# USB_USB_DWC3_53910000h register map
Vendor: Texas Instruments
Registers are 32-bit, read-write, reset 0x0 unless marked. A register's access mark holds for its fields unless they carry their own. Offsets are as the file gives them; [hi:lo] are bit positions; {n}, {i} and the like mark numbered series; 'fields as' and 'values as' point back to an identical list; <NAME> marks a mode.

## USB_DWC3 (part 2 of 2)
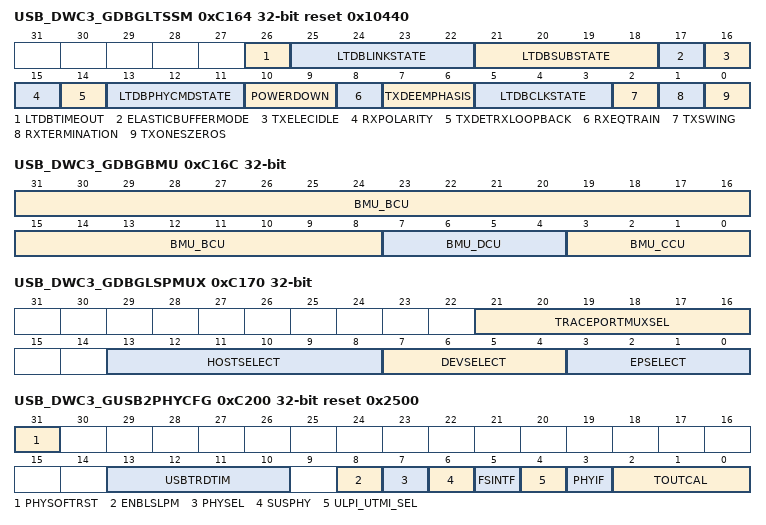
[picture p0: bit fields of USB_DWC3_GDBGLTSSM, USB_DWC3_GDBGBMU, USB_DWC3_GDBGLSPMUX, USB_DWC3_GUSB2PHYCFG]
0xC164 USB_DWC3_GDBGLTSSM ro reset 0x10440 — Global Debug LTSSM (Link Training Super-speed State Machine) Port number is defined by GDBGFIFOSPACE.PortSelect[3:0].
  [26] LTDBTIMEOUT — LTSSM Debug Timeout
  [25:22] LTDBLINKSTATE — LTSSM Debug: Link State
  [21:18] LTDBSUBSTATE — LTSSM Debug: Link Sub-State. Note that the actual reset value [0x0] changes before the register can be read out.
  [17] ELASTICBUFFERMODE — Debug PIPE Status: ElasticBufferMode
  [16] TXELECIDLE — Debug PIPE Status: TxElecIdle
  [15] RXPOLARITY — Debug PIPE Status: RxPolarity
  [14] TXDETRXLOOPBACK — Debug PIPE Status: TxDetRxLoopback
  [13:11] LTDBPHYCMDSTATE — LTSSM Debug Phy Command State.
  [10:9] POWERDOWN — Debug PIPE Status: PowerDown
  [8] RXEQTRAIN — Debug PIPE Status: RxEqTrain
  [7:6] TXDEEMPHASIS — Debug PIPE Status: TxDeemphasis
  [5:3] LTDBCLKSTATE — LTSSM Debug Clock State
  [2] TXSWING — Debug PIPE Status: TxSwing
  [1] RXTERMINATION — Debug PIPE Status: RxTermination
  [0] TXONESZEROS — Debug PIPE Status: TxOnesZeros
0xC168 USB_DWC3_GDBGLNMCC ro — Global Debug LNMCC (Link layer /MAC layer Control).
  [8:0] LNMCC_BERC — LNMCC Bit Error Rate Count: BER information for port selected in GDBGFIFOSPACE.PortSelect
0xC16C USB_DWC3_GDBGBMU ro — Global Debug BMU (Buffer Management Unit).
  [31:8] BMU_BCU — BMU Bus Control Unit: Debug information
  [7:4] BMU_DCU — BMU Datapath Control Unit: Debug information
  [3:0] BMU_CCU — BMU Control-path Control Unit: Debug information
0xC170 USB_DWC3_GDBGLSPMUX — Global Debug LSP MUX, for internal use only.
  [21:16] TRACEPORTMUXSEL — Select the 64-bit analyzer trace vector. Not sensitive to warm reset [ie including software reset], only to power-on reset.
  [13:8] HOSTSELECT — Host LSP Select[13:8]. Valid only in Host mode.
  [7:4] DEVSELECT — Host LSP Select[7:4] in Host mode. Device LSP Select in Device mode
  [3:0] EPSELECT — Host LSP Select[3:0] in Host mode. Device LSP Select in Device mode
0xC174 USB_DWC3_GDBGLSP ro — Global Debug LSP, for internal use only.
  [31:0] DEBUG — LSP debug information
0xC178 USB_DWC3_GDBGEPINFO0 ro — Global Debug Endpoint Information Register 0
  [31:0] DEBUG — EP debug information
0xC17C USB_DWC3_GDBGEPINFO1 ro — Global Debug Endpoint Information Register 1
  [31:0] DEBUG — EP debug information
0xC180 USB_DWC3_GPRTBIMAP_HSLO — Global Port to USB Instance Mapping Register, High-Speed, low bits [31:0].
  [3:0] BINUM1 — HS USB Instance Number for Port number 1. Application-programmable ID field.
0xC184 USB_DWC3_GPRTBIMAP_HSHI access not given reset not defined — Global Port to USB Instance Mapping Register, High-Speed, high bits [63:32].
0xC188 USB_DWC3_GPRTBIMAP_FSLO — Global Port to USB Instance Mapping Register, Full/low-Speed, low bits [31:0].
  [3:0] BINUM1 — FS USB Instance Number for Port number 1. Application-programmable ID field.
0xC18C USB_DWC3_GPRTBIMAP_FSHI access not given reset not defined — Global Port to USB Instance Mapping Register, Full/low-Speed, high bits [63:32].
0xC200 USB_DWC3_GUSB2PHYCFG access per field reset 0x2500 — Global USB2 (UTMI/ULPI) PHY configuration.
  [31] PHYSOFTRST rw — PHY Soft Reset. Active-high, fully static software reset for UTMI USB2 transceiver.
  [13:10] USBTRDTIM rw — USB 2.0 Turnaround Time, in PHY clock cycles. Specifies the response time for a MAC request to the Packet FIFO Controller [PFC] to fetch data from the DFIFO [SPRAM].
  [8] ENBLSLPM rw — Enable UTMI Sleep. Controls assertion of utmi_sleep_n, utmi_l1_suspend_n outputs to the PHY when in the L1 state.
  [7] PHYSEL ro — PHY Select. [HS vs. serial]: Unused, since serial PHY is not supported.
  [6] SUSPHY rw — Suspend enable for USB2.0 HS/FS/LS PHY [ULPI or UTMI]. Set to 1 only after core initialization is complete.
  [5] FSINTF ro — Full-Speed Serial Interface Select. UNUSED.
  [4] ULPI_UTMI_SEL ro — ULPI vs. UTMI+ Select
  [3] PHYIF rw — PHY Interface. DO NOT USE. If UTMI+ is selected, configures 8- or 16-bit interface. If ULPI is selected, configures SDR or DDR mode.
  [2:0] TOUTCAL rw — HS/FS Timeout Calibration. The number of PHY clocks, as indicated by the application in this field, is multiplied by a bit-time factor. This factor is added to the high- speed/full-speed interpacket timeout duration in the core to account for additional delays introduced by the PHY. This may be required, since the delay introduced by the PHY in generating the linestate condition may vary among PHYs. The USB standard timeout value for high-speed operation is 736 to 816 [inclusive] bit times. The USB standard timeout value for full-speed operation is 16 to 18 [inclusive] bit times. The application must program this field based on the speed of connection. The number of bit times added per PHY clock are: High-speed operation: 8 bit times per 60-MHz PHY clock cycle Full-speed operation: [depending on clock speed] 0.2 bit times per 60-MHz PHY clock cycle 0.25 bit times per 48-MHz PHY clock cycle
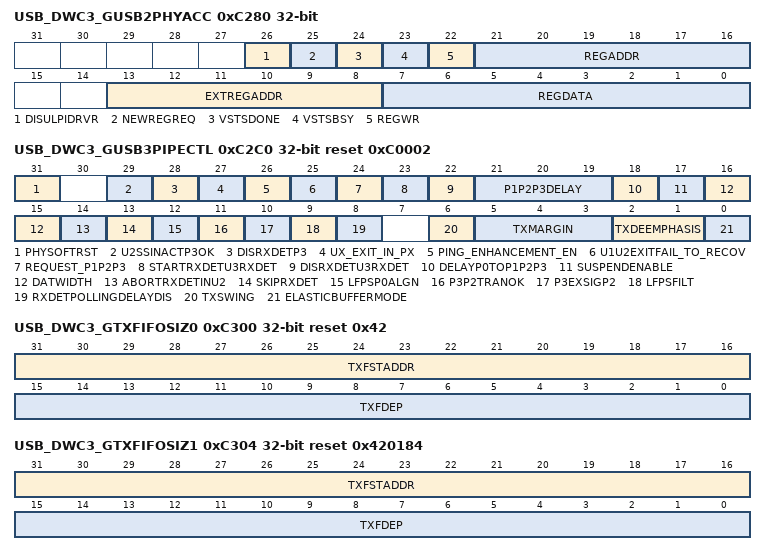
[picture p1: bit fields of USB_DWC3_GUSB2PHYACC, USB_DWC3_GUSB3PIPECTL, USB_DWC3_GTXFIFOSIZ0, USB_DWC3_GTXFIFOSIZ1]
0xC280 USB_DWC3_GUSB2PHYACC access per field — Global USB2 PHY Access.
  [26] DISULPIDRVR ro — Disable ULPI Drivers, for carkit mode. Auto-cleared. NOT USED.
  [25] NEWREGREQ rw — New Register Request. Auto-cleared.
  [24] VSTSDONE ro — VStatus Done
  [23] VSTSBSY ro — VStatus Busy
  [22] REGWR rw — Register Write
  [21:16] REGADDR rw — Register Address. ULPI PHY register address for immediate PHY Register Set access. Set to 6h2F for Extended PHY Register Set access.
  [13:8] EXTREGADDR rw — ULPI: PHY extended register address. UTMI+: unused
  [7:0] REGDATA rw — Register Data [read and write data]
0xC2C0 USB_DWC3_GUSB3PIPECTL access per field reset 0xC0002 — Global USB3 PIPE Control.
  [31] PHYSOFTRST rw — PHY Soft Reset. Active-high, fully static software reset for PIPE USB3 transceiver. Recommendation is to use the core's SW reset instead, or simultaneously.
  [29] U2SSINACTP3OK rw — Use mode P3 for U2/SSInactive states
  [28] DISRXDETP3 rw — Disabled Rx Detection in P3 mode [in the PHY]
  [27] UX_EXIT_IN_PX rw — Workaround for SS PHY injecting a glitch on RxElecIdle while receiving Ux exit LFPS, and PowerDown change is in progress.
  [26] PING_ENHANCEMENT_EN rw — Ping Enhancement Enable: Extended downstream port U1 ping receive timeout. Invalid for Upstream port.
  [25] U1U2EXITFAIL_TO_RECOV rw — Enhancement to prevent interoperability issue in case of incorrect LFPS handshake by the remote link.
  [24] REQUEST_P1P2P3 rw — Control the systematic request of P1/P2/P3 for U1/U2/U3
  [23] STARTRXDETU3RXDET rw — Manual control for periodic Rx detection required in U3 and Rx.Detect, host mode.
  [22] DISRXDETU3RXDET rw — Disable the HW-scheduled periodic Rx detection required in U3 and SS.Disabled, for host mode.
  [21:19] P1P2P3DELAY rw — If DelayP0toP1P2P3=1, delays the transition to P1/P2/P3 when entering U1/U2/U3 until P1P2P3Delay*8b10b errors occur, or RxValid=0 on PIPE.
  [18] DELAYP0TOP1P2P3 rw — Delay PHY change from P0 to P1/P2/P3 when link state changes from U0 to U1/U2/U3, respectively.
  [17] SUSPENDENABLE rw — Suspend Enable for USB3.0 SS PHY. Set to 1 only after core initialization is complete.
  [16:15] DATWIDTH ro — PIPE Data Width [input from phy: refer to PIPE standard]. Field updated to the input's value immediately after reset.
  [14] ABORTRXDETINU2 rw — Abort Rx Detect in U2. For Downstream port only.
  [13] SKIPRXDET rw — Skip Rx Detect. When set, the core skips Rx Detection if pipe signal 'RxElecIdle' is low. Skip is defined as waiting for the appropriate timeout, then repeating the operation.
  [12] LFPSP0ALGN rw — LFPS P0 Align. When set to1: The core deasserts LFPS transmission on the clock edge that it requests Phy power state 0 when exiting U1, U2, or U3 low power states. Otherwise, LFPS transmission is asserted one clock earlier. - The core requests symbol transmission two pipe_rx_pclks periods after The Phy asserts PhyStatus as a result of The Phy switching from Q1 or Q2 state to P0 state.
  [11] P3P2TRANOK rw — P3-to-P2 Transitions OK
  [10] P3EXSIGP2 rw — PHY power state behaviour upon U3 exit handshake.
  [9] LFPSFILT rw — LFPS Filter. When set, filter LFPS reception with pipe 'RxValid' signal in PHY power state P0, that is, ignore LFPS reception from the PHY unless both pipe signals 'RxElecIdle' and 'RxValid' are deasserted.
  [8] RXDETPOLLINGDELAYDIS rw — Disable 400us delay from Rx.Detect to Polling.LFPS
  [6] TXSWING rw — Tx Swing [output to phy: refer to PIPE standard]
  [5:3] TXMARGIN rw — Tx Margin[2:0] [output to phy: refer to PIPE standard]
  [2:1] TXDEEMPHASIS rw — Tx Deemphasis [output to phy: refer to PIPE standard]. The value driven to the PHY is controlled by the LTSSM during USB3 Compliance mode.
  [0] ELASTICBUFFERMODE rw — Elastic Buffer Mode [output to phy: refer to PIPE standard]
0xC300 USB_DWC3_GTXFIFOSIZ0 reset 0x42 — Global Transmit FIFO Size #0: FIFO mapping in RAM1, from staddr to (staddr+dep-1).
  [31:16] TXFSTADDR — Transmit FIFO RAM Start Address, in 64-bit RAM words
  [15:0] TXFDEP — Transmit FIFO Depth, in 64-bit RAM words
0xC304 USB_DWC3_GTXFIFOSIZ1 reset 0x420184 — Global Transmit FIFO Size #1: FIFO mapping in RAM1, from staddr to (staddr+dep-1).
  fields as USB_DWC3_GTXFIFOSIZ0
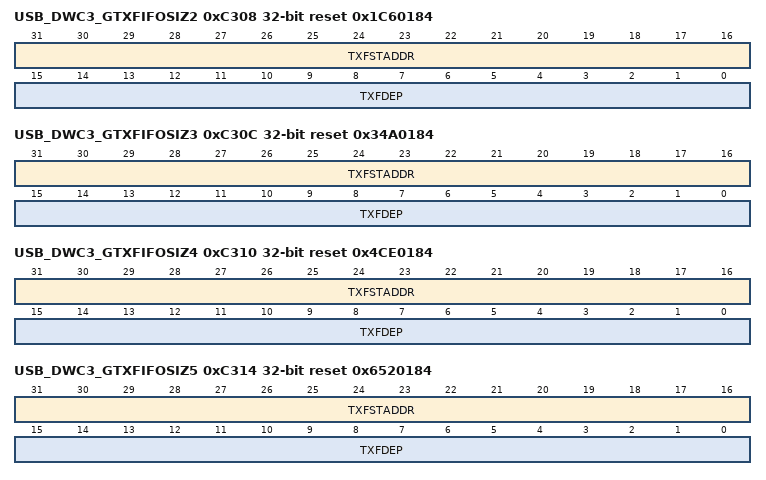
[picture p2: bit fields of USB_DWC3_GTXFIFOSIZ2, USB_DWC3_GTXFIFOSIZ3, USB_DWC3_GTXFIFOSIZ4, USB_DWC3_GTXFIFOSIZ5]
0xC308 USB_DWC3_GTXFIFOSIZ2 reset 0x1C60184 — Global Transmit FIFO Size #2: FIFO mapping in RAM1, from staddr to (staddr+dep-1).
  fields as USB_DWC3_GTXFIFOSIZ0
0xC30C USB_DWC3_GTXFIFOSIZ3 reset 0x34A0184 — Global Transmit FIFO Size #3: FIFO mapping in RAM1, from staddr to (staddr+dep-1).
  fields as USB_DWC3_GTXFIFOSIZ0
0xC310 USB_DWC3_GTXFIFOSIZ4 reset 0x4CE0184 — Global Transmit FIFO Size #4: FIFO mapping in RAM1, from staddr to (staddr+dep-1).
  fields as USB_DWC3_GTXFIFOSIZ0
0xC314 USB_DWC3_GTXFIFOSIZ5 reset 0x6520184 — Global Transmit FIFO Size #5: FIFO mapping in RAM1, from staddr to (staddr+dep-1).
  fields as USB_DWC3_GTXFIFOSIZ0
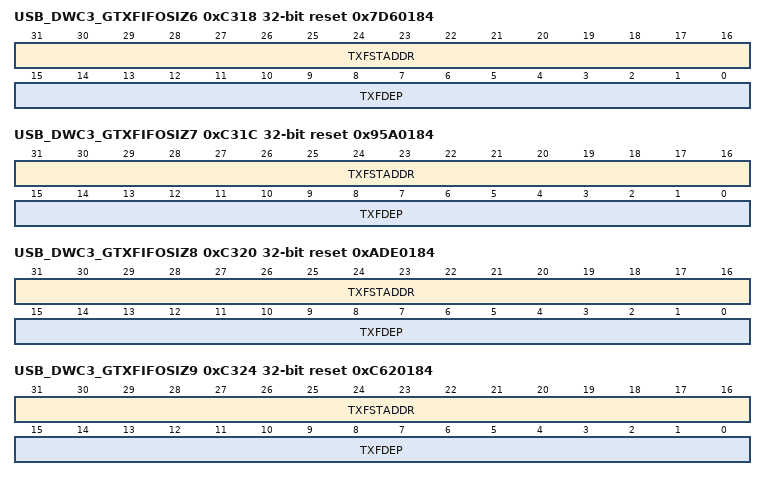
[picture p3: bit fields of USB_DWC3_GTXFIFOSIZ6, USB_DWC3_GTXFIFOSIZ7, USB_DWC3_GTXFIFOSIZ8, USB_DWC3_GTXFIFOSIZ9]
0xC318 USB_DWC3_GTXFIFOSIZ6 reset 0x7D60184 — Global Transmit FIFO Size #6: FIFO mapping in RAM1, from staddr to (staddr+dep-1).
  fields as USB_DWC3_GTXFIFOSIZ0
0xC31C USB_DWC3_GTXFIFOSIZ7 reset 0x95A0184 — Global Transmit FIFO Size #7: FIFO mapping in RAM1, from staddr to (staddr+dep-1).
  fields as USB_DWC3_GTXFIFOSIZ0
0xC320 USB_DWC3_GTXFIFOSIZ8 reset 0xADE0184 — Global Transmit FIFO Size #8: FIFO mapping in RAM1, from staddr to (staddr+dep-1).
  fields as USB_DWC3_GTXFIFOSIZ0
0xC324 USB_DWC3_GTXFIFOSIZ9 reset 0xC620184 — Global Transmit FIFO Size #9: FIFO mapping in RAM1, from staddr to (staddr+dep-1).
  fields as USB_DWC3_GTXFIFOSIZ0
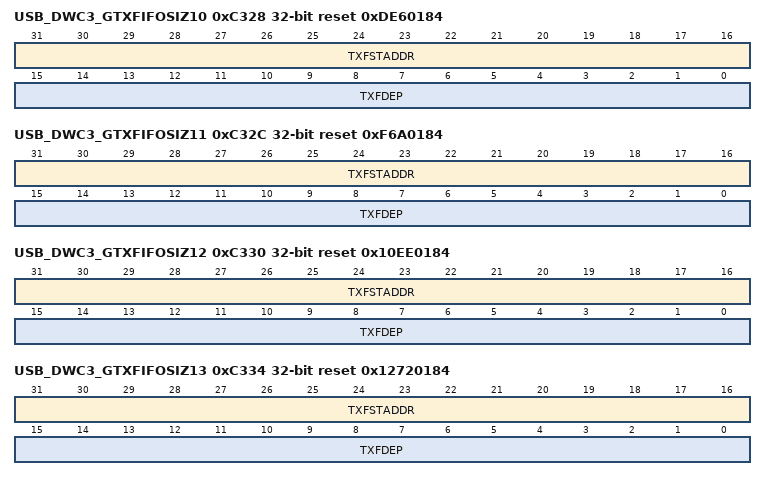
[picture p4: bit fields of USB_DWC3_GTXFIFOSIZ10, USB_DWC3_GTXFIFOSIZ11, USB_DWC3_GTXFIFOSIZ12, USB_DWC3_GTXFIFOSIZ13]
0xC328 USB_DWC3_GTXFIFOSIZ10 reset 0xDE60184 — Global Transmit FIFO Size #10: FIFO mapping in RAM1, from staddr to (staddr+dep-1).
  fields as USB_DWC3_GTXFIFOSIZ0
0xC32C USB_DWC3_GTXFIFOSIZ11 reset 0xF6A0184 — Global Transmit FIFO Size #11: FIFO mapping in RAM1, from staddr to (staddr+dep-1).
  fields as USB_DWC3_GTXFIFOSIZ0
0xC330 USB_DWC3_GTXFIFOSIZ12 reset 0x10EE0184 — Global Transmit FIFO Size #12: FIFO mapping in RAM1, from staddr to (staddr+dep-1).
  fields as USB_DWC3_GTXFIFOSIZ0
0xC334 USB_DWC3_GTXFIFOSIZ13 reset 0x12720184 — Global Transmit FIFO Size #13: FIFO mapping in RAM1, from staddr to (staddr+dep-1).
  fields as USB_DWC3_GTXFIFOSIZ0
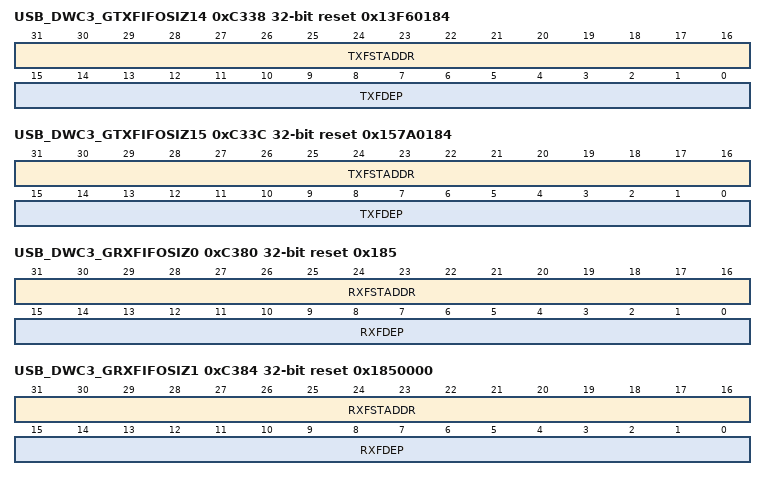
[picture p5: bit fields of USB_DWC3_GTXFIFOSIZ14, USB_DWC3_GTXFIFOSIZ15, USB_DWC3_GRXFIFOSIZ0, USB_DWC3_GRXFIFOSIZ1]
0xC338 USB_DWC3_GTXFIFOSIZ14 reset 0x13F60184 — Global Transmit FIFO Size #14: FIFO mapping in RAM1, from staddr to (staddr+dep-1).
  fields as USB_DWC3_GTXFIFOSIZ0
0xC33C USB_DWC3_GTXFIFOSIZ15 reset 0x157A0184 — Global Transmit FIFO Size #15: FIFO mapping in RAM1, from staddr to (staddr+dep-1).
  fields as USB_DWC3_GTXFIFOSIZ0
0xC380 USB_DWC3_GRXFIFOSIZ0 reset 0x185 — Global Receive FIFO Size #0: FIFO mapping in RAM, from staddr to (staddr+dep-1).
  [31:16] RXFSTADDR — Receive FIFO RAM Start Address, in 64-bit RAM words.
  [15:0] RXFDEP — Receive FIFO Depth, in 64-bit RAM words
0xC384 USB_DWC3_GRXFIFOSIZ1 reset 0x1850000 — Global Receive FIFO Size #1: FIFO mapping in RAM, from staddr to (staddr+dep-1).
  fields as USB_DWC3_GRXFIFOSIZ0
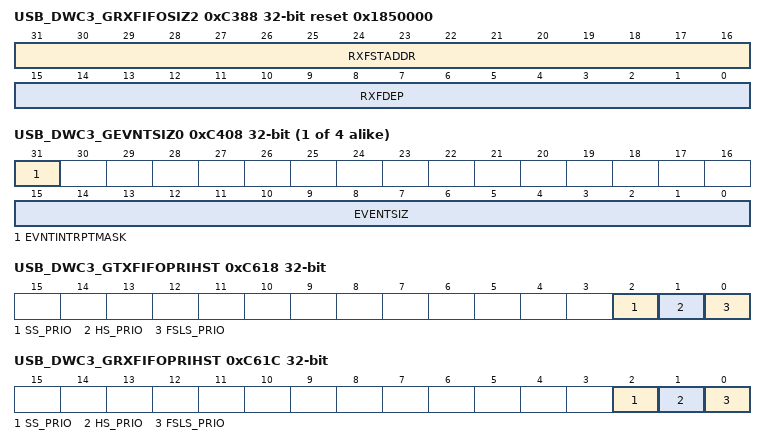
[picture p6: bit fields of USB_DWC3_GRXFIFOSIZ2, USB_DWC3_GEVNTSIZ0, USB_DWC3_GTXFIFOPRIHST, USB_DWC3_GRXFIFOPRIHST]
0xC388 USB_DWC3_GRXFIFOSIZ2 reset 0x1850000 — Global Receive FIFO Size #2: FIFO mapping in RAM, from staddr to (staddr+dep-1).
  fields as USB_DWC3_GRXFIFOSIZ0
{0xC400+0x10*i} USB_DWC3_GEVNTADRLO{i} (i=0..3) — Global Event Address: Lower 32 bits of start address of the external memory for the Event Buffer. During operation, hardware does not update this address.
  [31:0] EVNTADRLO — EVNTADR[31:0]
{0xC404+0x10*i} USB_DWC3_GEVNTADRHI{i} (i=0..3) — Global Event Address: Upper 32 bits of start address of the external memory for the Event Buffer. During operation, hardware does not update this address.
  [31:0] EVNTADRHI — EVNTADR[64:32]
{0xC408+0x10*i} USB_DWC3_GEVNTSIZ{i} (i=0..3) — Global Event Buffer Size.
  [31] EVNTINTRPTMASK — Event Interrupt Mask. Prevents the interrupt from being generated when set to '1'. The events are queued wven when the mask is set.
  [15:0] EVENTSIZ — Event Buffer Size. Size of the Event Buffer, in bytes must be a multiple of 4. Programmed by SW once during initialization.
{0xC40C+0x10*i} USB_DWC3_GEVNTCOUNT{i} (i=0..3) — Global Event Buffer Count.
  [15:0] EVNTCOUNT — Event Count. When read, returns the number of valid events in the Event Buffer [in bytes]. When written, hardware decrements the count by the value written. The interrupt remains active while count is not 0.
0xC600 USB_DWC3_GHWPARAMS8 ro reset 0x864 — Global hardware parameters #8
  [31:0] DWC_USB3_DCACHE_DEPTH_INFO — Depth of data cache, in 64-bit words [fixed], mapped in RAM0
0xC604 USB_DWC3_GHWPARAMS9 ro — Global hardware parameters #9
0xC610 USB_DWC3_GTXFIFOPRIDEV — Global Device TX FIFO DMA Priority Register.
  [15:0] EP_PRIO — Tx [IN] endpoint priority, device mode. Set bit #N to 1 to prioritize IN endpoint #N.
0xC618 USB_DWC3_GTXFIFOPRIHST — Global Host TX FIFO DMA Priority Register.
  [2] SS_PRIO — Host-mode USB3 SS scheduler priority for Tx RAM buffer access
  [1] HS_PRIO — Host-mode USB2 HS scheduler priority for Tx RAM buffer access
  [0] FSLS_PRIO — Host-mode USB2 FS/LS scheduler priority for Tx RAM buffer access
0xC61C USB_DWC3_GRXFIFOPRIHST — Global Host RX FIFO DMA Priority Register.
  [2] SS_PRIO — Host-mode USB3 SS scheduler priority for Rx RAM buffer access
  [1] HS_PRIO — Host-mode USB2 HS scheduler priority for Rx RAM buffer access
  [0] FSLS_PRIO — Host-mode USB2 FS/LS scheduler priority for Rx RAM buffer access
0xC620 USB_DWC3_GFIFOPRIDBC — Global Host Debug Capability DMA Priority Register.
  [1:0] DBC_PRIO — Host-mode DbC scheduler priority for RAM buffer access [vs. USB3 SS 'regular' host priority]
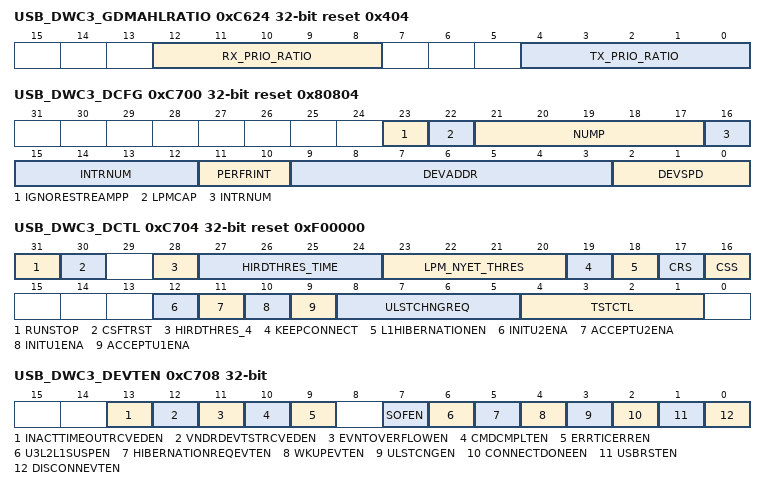
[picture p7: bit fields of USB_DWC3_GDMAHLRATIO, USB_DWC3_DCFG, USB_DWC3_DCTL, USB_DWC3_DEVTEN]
0xC624 USB_DWC3_GDMAHLRATIO reset 0x404 — Global Host FIFO DMA High-Low Priority Ratio Register. The greater the value, the higher the relative priority of USB3 SS vs. USB2 HS+FSLS.
  [12:8] RX_PRIO_RATIO — Host RXFIFO DMA High-Low Priority Ratio
  [4:0] TX_PRIO_RATIO — Host TXFIFO DMA High-Low Priority Ratio
0xC700 USB_DWC3_DCFG reset 0x80804 — Device Configuration: configures the core in Device mode after power-on or after certain control commands or enumeration. Do not change after initial programming.
  [23] IGNORESTREAMPP — Ignore Packet-Pending for Stream management. From stream-capable bulk endpoints only.
  [22] LPMCAP — Link Power Management [LPM] Capability.
  [21:17] NUMP — Number of Receive Buffers. Indicates number of receive buffers to be reported in ACK TP. Value based on RxFIFO size, buffer sizes programmed in descriptors, and system latency.
  [16:12] INTRNUM — Interrupt Number. Interrupt/EventQ number on which non-endpoint-specific device related interrupts [see DEVT] are generated.
  [11:10] PERFRINT — Periodic Frame Interrupt. Time within a [micro]frame when the application must be notified using the End Of Periodic Frame Interrupt, which can be used to determine if all the periodic [isochronous, interrupt] traffic for that [micro]frame is complete.
  [9:3] DEVADDR — Device Address. Configure upon set-address USB command, clear to 0 upon USB reset.
  [2:0] DEVSPD — Device Speed: USB speed at which the core should connect. Actual bus speed is determined only after chirp completion, based on the speed of the attached USB host.
0xC704 USB_DWC3_DCTL access per field reset 0xF00000 — Device Control.
  [31] RUNSTOP rw
  [30] CSFTRST rw — Core Soft Reset. Auto-cleared. The reset has the following effect: - Interrupts are cleared. - MMR are cleared except: GSTS, GSNPSID, GGPIO, GUID, GUSB2PHYCFG, GUSB3PIPECTL, DCFG, DCTL, DEVTEN, DSTS. -TxFIFOs and RxFIFO are flushed. - state machines are reset to The idle state, except The SoC target - Transactions on The SoC bus Master are terminated after completion. - Transactions on The USB are terminated immediately.
  [28] HIRDTHRES_4 rw — Host Initiated Resume Duration [HIRD] Threshold, MSbit: See HIRDTHRES_time
  [27:24] HIRDTHRES_TIME rw — Host Initiated Resume Duration [HIRD] Threshold, LSBits = timeout value. utmi_l1_suspend_n is asserted in L1 when : [HIRD value >= HIRDThres_time] and [HIRDThres_4=1]. utmi_sleep_n is asserted in L1 when : [HIRD value < HIRDThres_time] or [HIRDThres_4=0]
  [23:20] LPM_NYET_THRES rw — LPM NYET Response Threshold. Handshake response to LPM token specified by device application. Response depends on DCFG.LPMCap.
  [19] KEEPCONNECT ro — HIBERNATION / SAR FEATURE NOT IMPLEMENTED
  [18] L1HIBERNATIONEN ro — HIBERNATION / SAR FEATURE NOT IMPLEMENTED
  [17] CRS rw — Controller Restore State. DO NOT USE, SAR NOT IMPLEMENTED
  [16] CSS rw — Controller Save State. DO NOT USE, SAR NOT IMPLEMENTED
  [12] INITU2ENA rw — Initiate U2 Enable. Cleared to 0 by USB reset.
  [11] ACCEPTU2ENA rw — Accept U2 Enable. Cleared to 0 by USB reset.
  [10] INITU1ENA rw — Initiate U1 Enable. Cleared to 0 by USB reset.
  [9] ACCEPTU1ENA rw — Accept U1 Enable. Cleared to 0 by USB reset.
  [8:5] ULSTCHNGREQ rw — USB/Link State Change Request. A new request is indicated by a change of value. To issue the same request back-to-back, a 0 shall be written between the two requests. State change request result is reflected in DSTS.
  [4:1] TSTCTL rw — Test Control
0xC708 USB_DWC3_DEVTEN access per field — Device Event Enable: enables the generation of Device-Specific events (see DEVT).
  [13] INACTTIMEOUTRCVEDEN ro — U2 Inactive Timeout Received Event Enable
  [12] VNDRDEVTSTRCVEDEN rw — Vendor Device Test Received event Enable
  [11] EVNTOVERFLOWEN rw — Event Overflow event Enable
  [10] CMDCMPLTEN ro — Command Complete event Enable
  [9] ERRTICERREN rw — Erratic Error event Enable
  [7] SOFEN rw — Start of [micro]Frame event Enable. For debug only.
  [6] U3L2L1SUSPEN rw — U3/L2-L1 Suspend Event Enable
  [5] HIBERNATIONREQEVTEN rw — Hibernation Request Event Enable. DO NOT USE, HIBERNATION NOT IMPLEMENTED
  [4] WKUPEVTEN rw — Resume/Remote Wakeup Detected Event Enable.
  [3] ULSTCNGEN rw — USB/Link State Change event Enable
  [2] CONNECTDONEEN rw — Connection Done event Enable
  [1] USBRSTEN rw — USB Reset Enable
  [0] DISCONNEVTEN rw — Disconnct Event Enable
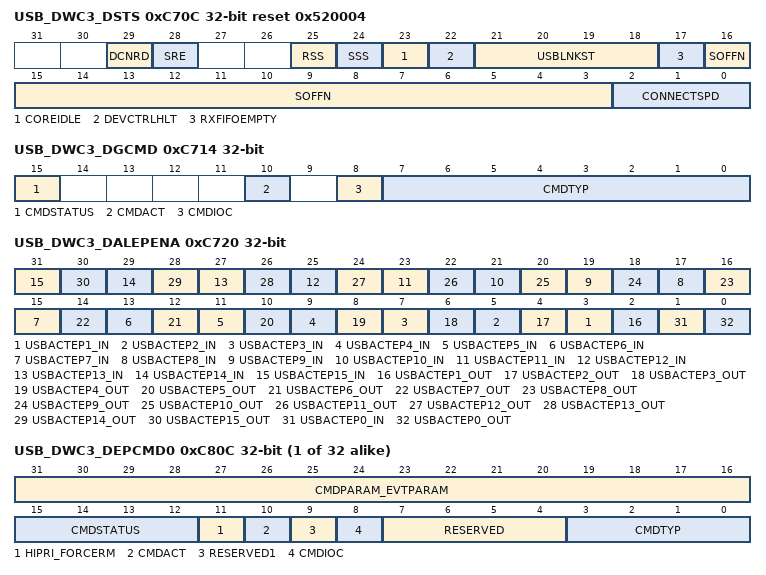
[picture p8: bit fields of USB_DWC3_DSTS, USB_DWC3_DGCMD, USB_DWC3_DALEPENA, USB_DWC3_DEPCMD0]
0xC70C USB_DWC3_DSTS ro reset 0x520004 — Device Status:.
  [29] DCNRD — Device Controller Not Ready
  [28] SRE — Save/Restore Error. NOT SUPPORTED.
  [25] RSS — Restore State Status, triggered by Writing 1 to RSS
  [24] SSS — Save State Status, triggered by Writing 1 to CSS
  [23] COREIDLE — Core Idle status. asserted when all RxFIFO data transferred to system memory, all completed descriptors are written, and all Event Counts are zero. Changes after reset, so that reset value may not match first readout.
  [22] DEVCTRLHLT — Device Controller Halted. Cleared [0] when the DCTL.RunStop is written to 1. Set [1] after DCTL.RunStop has been written to 0, core is idle and disconnect process is complete. When DevCtrlHlt =1, no Device events are generated.
  [21:18] USBLNKST — USB/Link State. Encoding depends on the connection speed [SS or HS/FS/LS]
  [17] RXFIFOEMPTY
  [16:3] SOFFN — Received Start Of Frame's Frame Number
  [2:0] CONNECTSPD — Connection Speed. USB speed at which the device has come up after speed detection through a chirp sequence.
0xC710 USB_DWC3_DGCMDPAR — Device Generic Command Parameter: To be programmed before or along with the device command itself.
  [31:0] PARAMETER — Parameter of the command
0xC714 USB_DWC3_DGCMD access per field — Device Generic Command: generic command interface to send link management packets and notifications.
  [15] CMDSTATUS ro — Command Status.
  [10] CMDACT rw — Command active. Auto-cleared.
  [8] CMDIOC wo — Command Interrupt On Complete. Event mapped to interrupt # DCFG.IntNum [register]. Reads return 0.
  [7:0] CMDTYP wo — Command Type. Reads return 0.
0xC720 USB_DWC3_DALEPENA — Device Active USB Endpoint Enable. Set each bit (1) to enable the corresponding endpoint. Bits 0 and 1 shall be set after USB reset, as they enable the control endpoint. All other bits shall be set according to enumeration, and cleared upon a USB reset.
  [2n+1] USBACTEP{n}_IN (n=1..15) — USB Activate Endpoint {n} IN
  [2n] USBACTEP{n}_OUT (n=1..15) — USB Activate Endpoint {n} OUT
  [1] USBACTEP0_IN — USB Activate Endpoint 0 IN [Control]
  [0] USBACTEP0_OUT — USB Activate Endpoint 0 OUT [Control]
{0xC6C0+0x10*i} USB_DWC3_DEPCMDPAR{i} (i=20..29) — Device Physical Endpoint-n Command Parameter 2.Must be programmed before issuing the command, if required by the command.
  [31:0] PARAMETER2 — Command-dependent
0xC804 USB_DWC3_DEPCMDPAR10 — Device Physical Endpoint-n Command Parameter 1Must be programmed before issuing the command, if required by the command.
  [31:0] PARAMETER1 — Command-dependent
{0xC808+0x10*i} USB_DWC3_DEPCMDPAR{i:02} (i=0..9) — Device Physical Endpoint-n Command Parameter 0Must be programmed before issuing the command, if required by the command.
  [31:0] PARAMETER0 — Command-dependent
{0xC80C+0x10*i} USB_DWC3_DEPCMD{i} access per field (i=0..31) — Device Physical Endpoint-n Command.
  [31:16] CMDPARAM_EVTPARAM rw — Read: Event Parameters, see Device-mode Endpoint Events [DEPEVT].Write: Command Parameters, command-dependent:DEPSTRTXFER on isoc EP: [31:16] microframe number for the first TRB [StartMicroFramNum]DEPSTRTXFER on stream-capable EP: [31:16] USB stream ID for the transfer [StreamID]DEPUPDXFER/DEPENDXFER: [22:16] Transfer resource index returned by HW upon transfer start [XferRscIdx]DEPSTARTCFG: [22:16] Transfer resource index assigned by SW upon new configuration start [XferRscIdx]
  [15:12] CMDSTATUS rw — Command Completion Status. Additional information about the command completion. Same format as bits 15:12 of the Endpoint Command Complete event.
  [11] HIPRI_FORCERM rw — HighPriority/ForceRM. Write-only field, reads return 0.Start Transfer command: HighPriority valueEnd Transfer command: ForceRM valueWrite 0 WR0HighPriority/ForceRM=0 Write 1 WR1HighPriority/ForceRM=1
  [10] CMDACT rw — Command Active. Auto-cleared.Read 0DONEEndpoint is ready to accept another command, CmdStatus field is valid.The effects of the previously-issued command may not all have taken place yet. Read 1 ACTIVECommand execution is being started.Write 1 EXEExecute the generic command.
  [9] RESERVED1 ro — Register is stored in RAM, so that the field is actually writable [value is still don't care].
  [8] CMDIOC rw — Command Interrupt On Complete. Event mapped tointerrupt # DEPCFG.IntNum [command].Reads return 0.Write 0NONo interrupt on complete Write 1IRQgeneric Endpoint Command Complete event issued after executing the command.
  [7:4] RESERVED ro — Register is stored in RAM, so that the field is actually writable [value is still don't care].
  [3:0] CMDTYP rw — Command Type.Write 0x1DEPCFGDEPCFG: Set Endpoint Configuration [64-bit parameter] Write 0x2DEPXFERCFGDEPXFERCFG: Set Endpoint Transfer Resource Configuration [32-bit parameter] Write 0x3DEPGETDSEQDEPGETDSEQ: Get Data Sequence Number [No Parameter] Write 0x4 DEPSSTALLDEPSETSTALL: Set Stall [No Parameter] Write 0x5 DEPCSTALLDEPCSTALL: Clear Stall [No Parameter] Write 0x6DEPSTRTXFERDEPSTRTXFER: Start Transfer [64-bit parameter] Write 0x7DEPUPDXFERDEPUPDXFER: Update Transfer [No Parameter] Write 0x8DEPENDXFERDEPENDXFER: End Transfer [No Parameter] Write 0x9DEPSTARTCFGDEPSTARTCFG: Start New Configuration [No Parameter]
0xC814 USB_DWC3_DEPCMDPAR11 — Device Physical Endpoint-n Command Parameter 1Must be programmed before issuing the command, if required by the command.
  [31:0] PARAMETER1 — Command-dependent
0xC824 USB_DWC3_DEPCMDPAR12 — Device Physical Endpoint-n Command Parameter 1Must be programmed before issuing the command, if required by the command.
  [31:0] PARAMETER1 — Command-dependent
0xC834 USB_DWC3_DEPCMDPAR13 — Device Physical Endpoint-n Command Parameter 1Must be programmed before issuing the command, if required by the command.
  [31:0] PARAMETER1 — Command-dependent
0xC844 USB_DWC3_DEPCMDPAR14 — Device Physical Endpoint-n Command Parameter 1Must be programmed before issuing the command, if required by the command.
  [31:0] PARAMETER1 — Command-dependent
0xC854 USB_DWC3_DEPCMDPAR15 — Device Physical Endpoint-n Command Parameter 1Must be programmed before issuing the command, if required by the command.
  [31:0] PARAMETER1 — Command-dependent
0xC864 USB_DWC3_DEPCMDPAR16 — Device Physical Endpoint-n Command Parameter 1Must be programmed before issuing the command, if required by the command.
  [31:0] PARAMETER1 — Command-dependent
0xC874 USB_DWC3_DEPCMDPAR17 — Device Physical Endpoint-n Command Parameter 1Must be programmed before issuing the command, if required by the command.
  [31:0] PARAMETER1 — Command-dependent
0xC884 USB_DWC3_DEPCMDPAR18 — Device Physical Endpoint-n Command Parameter 1Must be programmed before issuing the command, if required by the command.
  [31:0] PARAMETER1 — Command-dependent
0xC894 USB_DWC3_DEPCMDPAR19 — Device Physical Endpoint-n Command Parameter 1Must be programmed before issuing the command, if required by the command.
  [31:0] PARAMETER1 — Command-dependent
{0xBB80+0x10*i} USB_DWC3_DEPCMDPAR{i} (i=210..231) — Device Physical Endpoint-n Command Parameter 2.Must be programmed before issuing the command, if required by the command.
  [31:0] PARAMETER2 — Command-dependent
{0xC1C4+0x10*i} USB_DWC3_DEPCMDPAR{i} (i=110..131) — Device Physical Endpoint-n Command Parameter 1Must be programmed before issuing the command, if required by the command.
  [31:0] PARAMETER1 — Command-dependent
0xC8A8 USB_DWC3_DEPCMDPAR010 — Device Physical Endpoint-n Command Parameter 0Must be programmed before issuing the command, if required by the command.
  [31:0] PARAMETER0 — Command-dependent
0xC8B8 USB_DWC3_DEPCMDPAR011 — Device Physical Endpoint-n Command Parameter 0Must be programmed before issuing the command, if required by the command.
  [31:0] PARAMETER0 — Command-dependent
0xC8C8 USB_DWC3_DEPCMDPAR012 — Device Physical Endpoint-n Command Parameter 0Must be programmed before issuing the command, if required by the command.
  [31:0] PARAMETER0 — Command-dependent
0xC8D8 USB_DWC3_DEPCMDPAR013 — Device Physical Endpoint-n Command Parameter 0Must be programmed before issuing the command, if required by the command.
  [31:0] PARAMETER0 — Command-dependent
0xC8E8 USB_DWC3_DEPCMDPAR014 — Device Physical Endpoint-n Command Parameter 0Must be programmed before issuing the command, if required by the command.
  [31:0] PARAMETER0 — Command-dependent
0xC8F8 USB_DWC3_DEPCMDPAR015 — Device Physical Endpoint-n Command Parameter 0Must be programmed before issuing the command, if required by the command.
  [31:0] PARAMETER0 — Command-dependent
0xC908 USB_DWC3_DEPCMDPAR016 — Device Physical Endpoint-n Command Parameter 0Must be programmed before issuing the command, if required by the command.
  [31:0] PARAMETER0 — Command-dependent
0xC918 USB_DWC3_DEPCMDPAR017 — Device Physical Endpoint-n Command Parameter 0Must be programmed before issuing the command, if required by the command.
  [31:0] PARAMETER0 — Command-dependent
0xC928 USB_DWC3_DEPCMDPAR018 — Device Physical Endpoint-n Command Parameter 0Must be programmed before issuing the command, if required by the command.
  [31:0] PARAMETER0 — Command-dependent
{0xC808+0x10*i} USB_DWC3_DEPCMDPAR{i:03} (i=19..31) — Device Physical Endpoint-n Command Parameter 0Must be programmed before issuing the command, if required by the command.
  [31:0] PARAMETER0 — Command-dependent
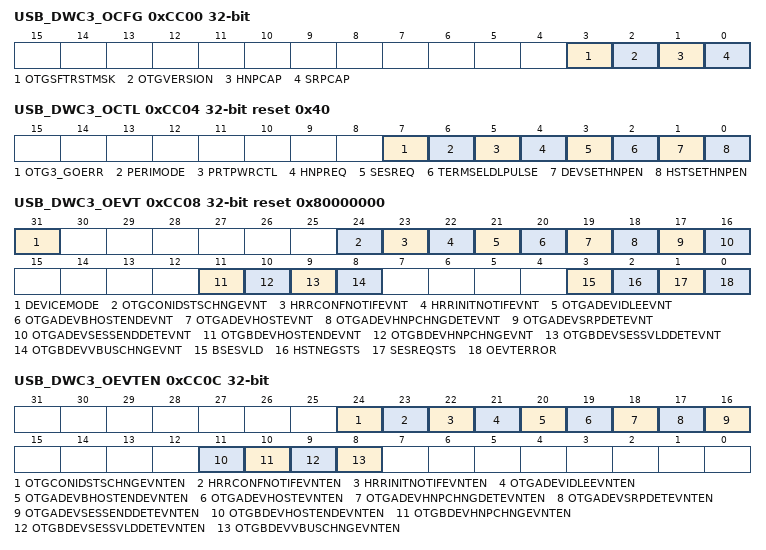
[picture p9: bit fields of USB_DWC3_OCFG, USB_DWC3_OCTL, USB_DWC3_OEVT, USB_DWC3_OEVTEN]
0xCC00 USB_DWC3_OCFG — OTG configuration.
  [3] OTGSFTRSTMSK — Protects OTG, PHY and VBUS filters from the following SW resets: xHCI USBCMD.HCRST [host], DCTL.CSftRst [device]. Note: In OTG2 applications, it is not recommended to program USBCMD.HCRST during role switch.
  [2] OTGVERSION — Debug, always write 0.
  [1] HNPCAP — HNP Capabilty Enable.
  [0] SRPCAP — SRP Capability enable. For A-device, SRP detection. For B-device, SRP generation.
0xCC04 USB_DWC3_OCTL reset 0x40 — OTG control. IMPORTANT NOTE: register is reinitialized upon ID change, but is not affected by a software reset.
  [7] OTG3_GOERR — To be set upon TRSP_ACK_ERR, TRSP_CNF_ERR, or TRSP_WRST_ERR timeout. Auto-cleared. OTG3: NOT IMPLEMENTED, DO NOT SET.
  [6] PERIMODE — Peripheral Mode. Program the core to work as a peripheral or as a host.
  [5] PRTPWRCTL — Port Power Control. Set or cleared by SW. Self-cleared in any of the following conditions: 1] transition to a_idle OTG state 2] aidl_bdis_tout event when in a_suspend OTG state 3] a_wait_bcon_tout event when in a_wait_bcon OTG state 4] transition to any b_* OTG state
  [4] HNPREQ — HNP Request. Set [1] by SW to initiate HNP request to the connected USB host. Clear [0] by SW upon either OEVT.OTGBDevBHostEndEvnt or OEVT.OTGBDevVBusChngEvnt.
  [3] SESREQ — Session Request. In the absence of OEVT.OTGBDevSessVldDetEvnt after a request, the application must wait for at least TB_SRP_FAIL [6 secs] before another request.
  [2] TERMSELDLPULSE — TermSelect Data Line Pulse. Alternate SRP data line pulsing method on UTMI interface.
  [1] DEVSETHNPEN — Device Set HNP Enable. To be set when HNP has been successfully enabled by the connected host, using the SetFeature.SetHNPEnable command.
  [0] HSTSETHNPEN — Host Set HNP Enable. To be set when HNP has been successfully enabled on the connected device, using the SetFeature.SetHNPEnable command.
0xCC08 USB_DWC3_OEVT access not given reset 0x80000000 — OTG Event: OTG interrupt status. All writable bits are cleared by writing a 1.
  [31] DEVICEMODE ro — Dual-role device's mode, based on iddig input.
  [24] OTGCONIDSTSCHNGEVNT — Connector ID status change event. Set in both A-device and B-device mode. (access R/W0TC)
  [23] HRRCONFNOTIFEVNT — Host Role Request Confirm Notifier Event. Set upon reception of HRR Device Notification TP with Confirm field set. Set in OTG3, SS, A-host or B-host mode only. OTG3: NOT IMPLEMENTED (access R/W0TC)
  [22] HRRINITNOTIFEVNT — Host Role Request Initiate Notifier Event. Set upon reception of HRR Device Notification TP with Initiate field set. Set in OTG3, SS, A-host or B-host mode only. OTG3: NOT IMPLEMENTED (access R/W0TC)
  [21] OTGADEVIDLEEVNT — A-device A-IDLE Event. Set when OTG FSM enters A-IDLE state from any other state. Set in A-device mode only. OTG3: NOT IMPLEMENTED (access R/W0TC)
  [20] OTGADEVBHOSTENDEVNT — A-device B-host End Event. Set when connected B-device has completed its B-host role and returns to B-peripheral. Set in A-device mode only. (access R/W0TC)
  [19] OTGADEVHOSTEVNT — A-device Host Event. Set when device enters host role, upon initial connect to B-device as well as upon HNP from A-peripheral to A-host. Set in A-device mode only. (access R/W0TC)
  [18] OTGADEVHNPCHNGDETEVNT — A-device HNP change Detected Event. Set when there is an HNP event. Set in A-device mode only. (access R/W0TC)
  [17] OTGADEVSRPDETEVNT — A-device SRP Detected Event. Set when SRP request from B-device is detected. Set in A-device mode only. (access R/W0TC)
  [16] OTGADEVSESSENDDETEVNT — A-device Session End Detected Event. Set when UTMI input 'a-vbus-valid' is deasserted [0]. Set in A-device mode only. (access R/W0TC)
  [11] OTGBDEVHOSTENDEVNT — B-device Host End Event. Set completing B-host role and returning to default B-peripheral role. Set in B-device mode only. (access R/W0TC)
  [10] OTGBDEVHNPCHNGEVNT — B-device HNP Change Event. Set upon [success of failure of an] HNP attempt. Set in B-device mode only. (access R/W0TC)
  [9] OTGBDEVSESSVLDDETEVNT — B-device Session Valid Detected Event. Set when B-device succeeds in starting a session. Set in B-device mode only. (access R/W0TC)
  [8] OTGBDEVVBUSCHNGEVNT — B-device VBUS Change Event. Set when UTMI input 'b-session-valid' transitions [to 0 or 1]. Set in B-device mode only. (access R/W0TC)
  [3] BSESVLD ro — B-Session Valid. Updated when OTGBDevVBUSChngEvnt is set.
  [2] HSTNEGSTS ro — Host Negociation Status. Updated when OTGADevHNPChngEvnt or OTGBDevHNPChngEvnt is set.
  [1] SESREQSTS ro — Session Request Status. Updated when OTGBDevSessVldDetEvnt is set.
  [0] OEVTERROR — No errors currently defined. (access R/W0TC)
0xCC0C USB_DWC3_OEVTEN — OTG Event Enable: OTG interrupt event enable.
  [24] OTGCONIDSTSCHNGEVNTEN — Connector ID Status Change Event Enable.
  [23] HRRCONFNOTIFEVNTEN — Host Role Request Confirm Notifier Event Enable. OTG3: NOT IMPLEMENTED
  [22] HRRINITNOTIFEVNTEN — Host Role Request Initiate Notifier Event Enable. OTG3: NOT IMPLEMENTED
  [21] OTGADEVIDLEEVNTEN — A-device A-IDLE Event Enable.
  [20] OTGADEVBHOSTENDEVNTEN — A-device B-host End Event Enable.
  [19] OTGADEVHOSTEVNTEN — A-device Host Event Enable.
  [18] OTGADEVHNPCHNGDETEVNTEN — A-device HNP change Detected Event Enable.
  [17] OTGADEVSRPDETEVNTEN — A-device SRP Detected Event Enable.
  [16] OTGADEVSESSENDDETEVNTEN — A-device Session End Detected Event Enable.
  [11] OTGBDEVHOSTENDEVNTEN — B-device Host End Event Enable.
  [10] OTGBDEVHNPCHNGEVNTEN — B-device HNP Change Event Enable.
  [9] OTGBDEVSESSVLDDETEVNTEN — B-device Session Valid Detected Event Enable.
  [8] OTGBDEVVBUSCHNGEVNTEN — B-device VBUS Change Event Enable.
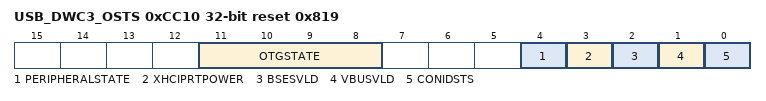
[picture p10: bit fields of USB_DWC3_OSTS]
0xCC10 USB_DWC3_OSTS ro reset 0x819 — OTG status.
  [11:8] OTGSTATE — OTG state machine state, for debug. Default value may vary depending on integration.
  [4] PERIPHERALSTATE — Current role of the controller
  [3] XHCIPRTPOWER — xHCI host Port Power. Reflects host bitfiled PORTSC.PP
  [2] BSESVLD — VBUS B-Session Valid status
  [1] VBUSVLD — VBUS Valid status
  [0] CONIDSTS — Connector ID Status. Default value may vary depending on integration.
